# AE302F80C1557LE_CM55_HE_View register map
Vendor: Alif Semiconductor; Series: E3; File version: 1.0
CPU: CM55 r1p0, selectable endian, MPU, FPU, double-precision FPU, DSP, VTOR, 8 interrupt priority bits, 1 SAU regions
Registers are 32-bit, read-write, reset 0x0 unless marked. A register's access mark holds for its fields unless they carry their own. Offsets are from the block's base; [hi:lo] are bit positions; 'fields as' and 'values as' point back to an identical list; <NAME> marks a mode.

## ETH (part 2 of 3)
Base 0x48100000
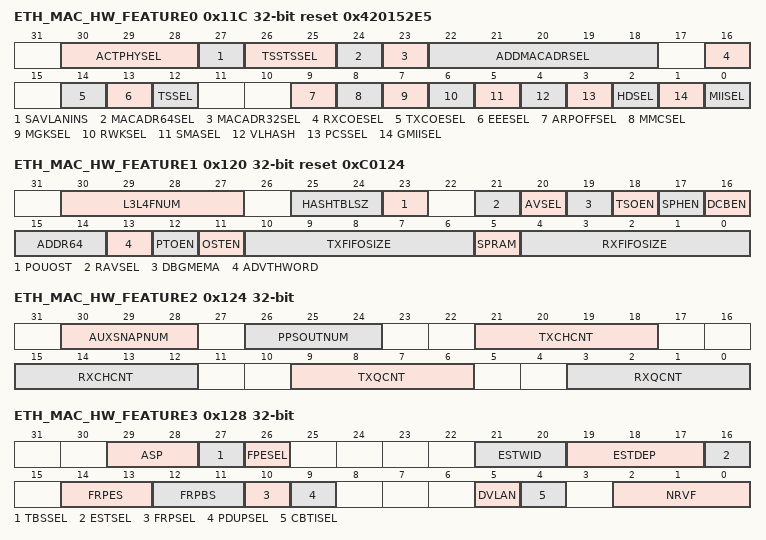
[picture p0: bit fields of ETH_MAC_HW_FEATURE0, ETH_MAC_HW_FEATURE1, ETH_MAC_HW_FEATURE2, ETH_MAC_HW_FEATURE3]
0x11C ETH_MAC_HW_FEATURE0 ro reset 0x420152E5 — ETH Hardware Feature Register 0
  [30:28] ACTPHYSEL — Active PHY Selected
    4=RMII
  [27] SAVLANINS — Source Address or VLAN Insertion Enable
    0=Source address or VLAN insertion disabled
  [26:25] TSSTSSEL — Timestamp System Time Source
    1=External
  [24] MACADR64SEL — MAC Addresses 64-127 Selected
    0=MAC addresses 64-127 disabled
  [23] MACADR32SEL — MAC Addresses 32-63 Selected
    0=MAC addresses 32-63 disabled
  [22:18] ADDMACADRSEL — MAC Addresses 1-31 Selected
    0=MAC addresses 1-31 disabled
  [16] RXCOESEL — Receive Checksum Offload Enabled
    1=Receive checksum offload enabled
  [14] TXCOESEL — Transmit Checksum Offload Enabled
    1=Transmit checksum offload enabled
  [13] EEESEL — Energy Efficient Ethernet Enabled
    0=Energy efficient ethernet disabled
  [12] TSSEL — IEEE 1588-2008 Timestamp Enabled
    1=IEEE 1588-2008 timestamp enabled
  [9] ARPOFFSEL — ARP Offload Enabled
    1=ARP offload disabled
  [8] MMCSEL — RMON Module Enable
    0=RMON module disabled
  [7] MGKSEL — PMT Magic Packet Enable
    1=PMT magic packet enabled
  [6] RWKSEL — PMT Remote Wake-up Packet Enable
    1=PMT remote wake-up packet enabled
  [5] SMASEL — SMA (MDIO) Interface
    1=SMA (MDIO) interface selected
  [4] VLHASH — VLAN Hash Filter Selected
    0=VLAN hash filter not selected
  [3] PCSSEL — PCS Registers (TBI, SGMII, or RTBI PHY interface)
    0=No PCS registers (TBI, SGMII, or RTBI PHY interface)
  [2] HDSEL — Half-duplex Support
    1=Half-duplex supported
  [1] GMIISEL — 1000 Mbps Support
    0=No 1000 Mbps supported
  [0] MIISEL — 10 or 100 Mbps Support
    1=10 or 100 Mbps supported
0x120 ETH_MAC_HW_FEATURE1 ro reset 0xC0124 — ETH Hardware Feature Register 1
  [30:27] L3L4FNUM — Total number of L3 or L4 Filters
    0=No L3 or L4 filter
  [25:24] HASHTBLSZ — Hash Table Size
    0=No hash table
  [23] POUOST — One Step for PTP over UDP/IP Enable
    0=One step for PTP over UDP/IP is disabled
  [21] RAVSEL — Rx Side Only AV Enable
    0=Rx side only AV is disabled
  [20] AVSEL — AV Enable
    0=AV fature is disabled
  [19] DBGMEMA — DMA Debug Registers Enable
    1=DMA debug registers enabled
  [18] TSOEN — TCP Segmentation Offload Enable
    1=TCP segmentation offload is enabled
  [17] SPHEN — Split Header Enable
    0=Split header is disabled
  [16] DCBEN — DCB Enable
    0=DCB is not selected
  [15:14] ADDR64 — Address Width.
    0=32
  [13] ADVTHWORD — IEEE 1588 High Word Register Enable
    0=IEEE 1588 high word register is disabled
  [12] PTOEN — PTP Offload Enable
    0=PTP offload is disabled
  [11] OSTEN — One-Step Timestamping Enable
    0=One-step timestamping is disabled
  [10:6] TXFIFOSIZE — MTL Transmit FIFO Size
    4=2048 bytes
  [5] SPRAM — Single Port RAM Enable
    1=Single port RAM is enabled
  [4:0] RXFIFOSIZE — MTL Receive FIFO Size
    4=2048 bytes
0x124 ETH_MAC_HW_FEATURE2 ro — ETH Hardware Feature Register 2
  [30:28] AUXSNAPNUM — Number of Auxiliary Snapshot Inputs
    0=No auxiliary input
  [26:24] PPSOUTNUM — Number of PPS Outputs
    0=No PPS output
  [21:18] TXCHCNT — Number of DMA Transmit Channels
    0=1 DMA Tx channel
  [15:12] RXCHCNT — Number of DMA Receive Channels
    0=1 DMA Rx channel
  [9:6] TXQCNT — Number of MTL Transmit Queues
    0=1 MTL Tx Queue
  [3:0] RXQCNT — Number of MTL Receive Queues
    0=1 MTL Rx Queue
0x128 ETH_MAC_HW_FEATURE3 ro — ETH Hardware Feature Register 3
  [29:28] ASP — Automotive Safety Package
    0=No safety features selected
  [27] TBSSEL — Time Based Scheduling Enable
    0=Time based scheduling disabled
  [26] FPESEL — Frame Preemption Enable
    0=Frame preemption disabled
  [21:20] ESTWID — Width of the Time Interval field in the Gate Control List
    0=Width not configured
  [19:17] ESTDEP — Depth of the Gate Control List
    0=No depth configured
  [16] ESTSEL — Enhancements to Scheduled Traffic Enable
    0=Enhancements to scheduling traffic disabled
  [14:13] FRPES — Flexible Receive Parser Table Entries size
    0=64 entries
  [12:11] FRPBS — Flexible Receive Parser Buffer size
    0=64 bytes
  [10] FRPSEL — Flexible Receive Parser Select
    0=Flexible receive parser disabled
  [9] PDUPSEL — Broadcast/Multicast Packet Duplication
    0=Broadcast/multicast packet duplication disabled
  [5] DVLAN — Double VLAN Tag Processing Select
    0=Double VLAN tag processing disabled
  [4] CBTISEL — Queue/Channel based VLAN tag insertion on Tx Enable
    0=Queue/Channel based VLAN tag insertion on Tx disabled
  [2:0] NRVF — Number of Extended VLAN Tag Filters Enable
    0=No extended Rx VLAN filters
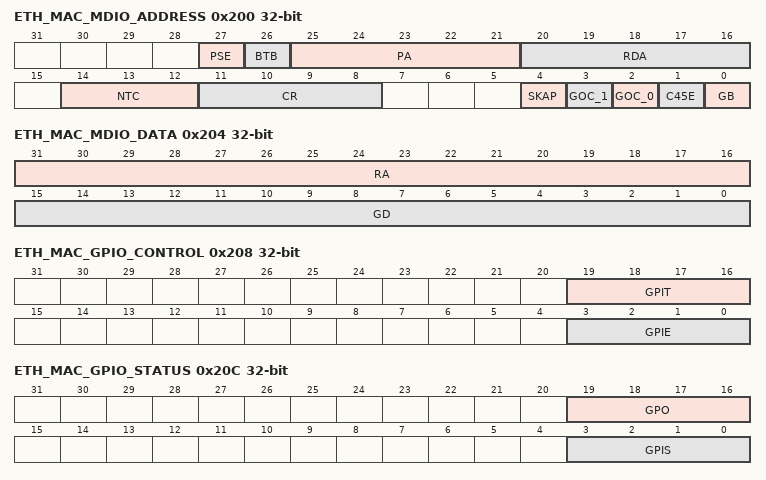
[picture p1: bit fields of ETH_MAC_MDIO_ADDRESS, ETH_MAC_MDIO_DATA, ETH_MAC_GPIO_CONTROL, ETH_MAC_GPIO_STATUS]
0x200 ETH_MAC_MDIO_ADDRESS — MDIO Address Register
  [27] PSE — Preamble Suppression Enable When this bit is set, the MDIO suppresses the 32-bit preamble and transmits MDIO packets with only 1 preamble bit. When this bit is 0, the MDIO packets always has 32 bits of preamble as defined in the IEEE specifications.
    0=Preamble suppression disabled; 1=Preamble suppression enabled
  [26] BTB — Back to Back Transactions When this bit is set and the NTC has value greater than 0, then the MAC informs the completion of a read or write command at the end of frame transfer (before the trailing clocks are transmitted). The software can thus initiate the next command which is executed immediately irrespective of the number trailing clocks generated for the previous frame. When this bit is reset, then the read/write command completion (GB is cleared) only after the trailing clocks are generated. In this mode, it is ensured that the NTC is always generated after each frame. This bit must not be set when NTC = 0.
    0=Back to back transactions disabled; 1=Back to back transactions enabled
  [25:21] PA — Physical Layer Address Specifies the address of the PHY device, out of the 32 possible PHY devices. Note: The value programmed in the C45E field determines if the PHY device is Clause 45 capable or Clause 22 capable.
  [20:16] RDA — Register or Device Address - For Clause 22 PHY: Specifies the PHY register address of the selected PHY device. - For Clause 45 PHY: Specifies the selected MDIO device.
  [14:12] NTC — Number of Trailing Clocks This field controls the number of trailing clock cycles generated on ETH_MDC after the end of MDIO frame transfer. The valid values can be from 0 to 7. When this field is programmed with a value of 0x3, MAC generates three clock cycles on the ETH_MDC line after the end of MDIO frame transfer.
  [11:8] CR — CSR Clock (CLK_CSR) Range The CLK_CSR range selection determines the frequency of the MDC clock (ETH_MDC) according to the CLK_CSR frequency: The suggested range of CLK_CSR frequency applicable for each value (when Bit 11 = 0) ensures that the ETH_MDC is approximately between 1.0 MHz to 2.5 MHz freqency range. When Bit 11 is set, the user can achieve a higher frequency of the ETH_MDC than the frequency limit of 2.5 MHz (specified in the IEEE 802.3 Specification) and program a clock divider of lower value. For example, when CLK_CSR is of 100 MHz frequency and the user programs the CR field to 0xA, the resultant ETH_MDC is of 12.5 MHz which is beyond the range specified in IEEE 802.3 Specification. Program the following values only if the interfacing chips support faster MDC clocks:
    0=CLK_CSR = 60-100 MHz; ETH_MDC = CLK_CSR / 42; 1=CLK_CSR = 100-150 MHz; ETH_MDC = CLK_CSR / 62; 2=CLK_CSR = 20-35 MHz; ETH_MDC = CLK_CSR / 16; 3=CLK_CSR = 35-60 MHz; ETH_MDC = CLK_CSR / 26; 4=CLK_CSR = 150-250 MHz; ETH_MDC = CLK_CSR / 102; 5=CLK_CSR = 250-300 MHz; ETH_MDC = CLK_CSR / 124; 6=CLK_CSR = 300-500 MHz; ETH_MDC = CLK_CSR / 204; 7=CLK_CSR = 500-800 MHz; ETH_MDC = CLK_CSR / 324; 8=CLK_CSR / 4; 9=CLK_CSR / 6; 10=CLK_CSR / 8; 11=CLK_CSR / 10; 12=CLK_CSR / 12; 13=CLK_CSR / 14; 14=CLK_CSR / 16; 15=CLK_CSR / 18
  [4] SKAP — Skip Address Packet When this bit is set, the MDIO does not send the address packets before read, write, or post-read increment address packets. This bit is valid only when the C45E bit is set.
    0=Skip address packet is disabled; 1=Skip address packet is enabled
  [3] GOC_1 — Operation Command 1 This is the higher bit of the operation command to the PHY. GOC_1 and GOC_O are encoded as follows: 0x0: Reserved 0x1: Write 0x2: Post read increment address for Clause 45 PHY 0x3: Read GOC_1 is encoded as follows: 0x0: Operation command 1 is disabled 0x1: Operation command 1 is enabled
  [2] GOC_0 — Operation Command 0 This is the lower bit of the operation command to the PHY. When in MDIO mode (MDIO master) this bit along with GOC_1 determines the operation to be performed to the PHY.
    0=Operation command 0 is disabled; 1=Operation command 0 is enabled
  [1] C45E — Clause 45 PHY Enable When this bit is set, Clause 45 capable PHY is connected to MDIO. When this bit is reset, Clause 22 capable PHY is connected to MDIO.
    0=Clause 45 PHY is disabled; 1=Clause 45 PHY is enabled
  [0] GB — RMII Busy The application sets this bit to instruct the MDIO to initiate a Read or Write access to the MDIO slave. The MAC clears this bit after the MDIO frame transfer is completed. Hence the software must not write or change any of the fields in ETH_MAC_MDIO_ADDRESS and ETH_MAC_MDIO_DATA registers as long as this bit is set. For write transfers, the application must first write 16-bit data in the ETH_MAC_MDIO_DATA[GD] field (and also ETH_MAC_MDIO_DATA[RA] field when the C45E bit is set) before setting this bit. When the C45E bit is set, it should also write into the ETH_MAC_MDIO_DATA[RA] field before initiating a read transfer. When a read transfer is completed (GB=0), the data read from the PHY register is valid in the ETH_MAC_MDIO_DATA[GD] field. Access restriction applies. Setting 1 sets. Self-cleared. Setting 0 has no effect.
    0=RMII busy is disabled; 1=RMII busy is enabled
0x204 ETH_MAC_MDIO_DATA — MDIO Data Register
  [31:16] RA — Register Address This field is valid only when the ETH_MAC_MDIO_ADDRESS[C45E] bit is set. It contains the Register Address in the PHY to which the MDIO frame is intended for.
  [15:0] GD — RMII Data This field contains the 16-bit data value read from the PHY after a Management Read operation or the 16-bit data value to be written to the PHY before a Management Write operation.
0x208 ETH_MAC_GPIO_CONTROL — GPIO Control Register
  [19:16] GPIT — GPI Type When a bit in this field is set, it indicates that the corresponding bit in the ETH_MAC_GPIO_STATUS[GPIS] field is of latched-low (LL) type. When a bit in this field is reset, it indicates that the corresponding bit in the ETH_MAC_GPIO_STATUS[GPIS] field is of latched-high (LH) type.
  [3:0] GPIE — GPI Interrupt Enable When a bit in this field is set and the programmed event (LL or LH) occurs on the corresponding bit in the ETH_MAC_GPIO_STATUS[GPIS] field, the ETH_MAC_INTERRUPT_STATUS[GPIIS] bit is set and an interrupt is generated on the ETH_SBD_IRQ signal. The ETH_MAC_INTERRUPT_STATUS[GPIIS] bit is cleared when the application reads the ETH_MAC_GPIO_STATUS[GPIS] field. When a bit in this field is reset, the ETH_MAC_INTERRUPT_STATUS[GPIIS] bit is not set when any event occurs on the corresponding bit in the ETH_MAC_GPIO_STATUS[GPIS] field.
0x20C ETH_MAC_GPIO_STATUS — GPIO Status Register
  [19:16] GPO — General Purpose Output When a bit in this field is set, it directly drives the corresponding bit of the GPO_O output port. When a bit in this field is reset, it does not directly drive the corresponding bit of the GPO_O output port.
  [3:0] GPIS — General Purpose Input Status This field gives the status of the signals connected to the GPI_I port. Each bit in this field is of the following types based on the setting of the corresponding bit in the ETH_MAC_GPIO_CONTROL[GPIT] field: - Latched-low (LL): This field is cleared when the corresponding GPI_I input becomes low. This field remains low until the application reads it after which this field reflects the current value of GPI_I input. - Latched-high (LH): This field is set when the corresponding GPI_I input becomes high. This field remains high until the application reads it after which this field reflects the current value of GPI_I input.
0x210 ETH_MAC_ARP_ADDRESS — ARP Address Register
  [31:0] ARPPA — ARP Protocol Address This field contains the IPv4 Destination Address of the MAC. This address is used for perfect match with the Protocol Address of Target field in the received ARP packet. This field is available only when the Enable IPv4 ARP Offload option is selected.
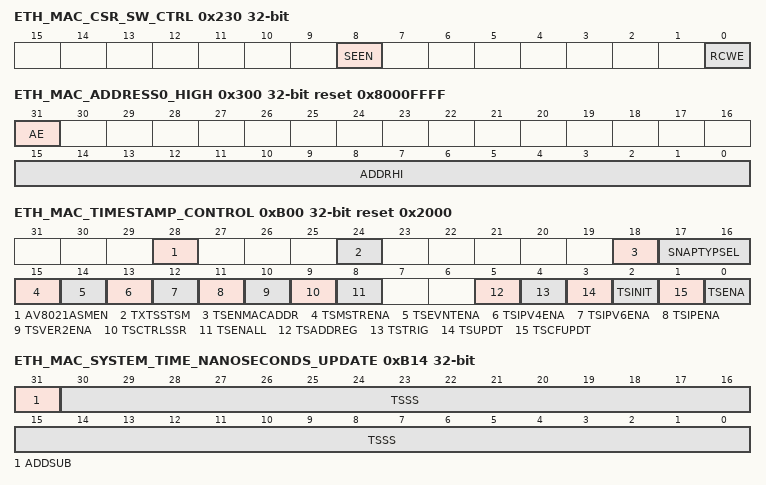
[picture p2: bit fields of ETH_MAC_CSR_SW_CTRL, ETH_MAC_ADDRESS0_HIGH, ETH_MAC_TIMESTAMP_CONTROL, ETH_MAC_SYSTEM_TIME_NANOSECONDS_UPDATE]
0x230 ETH_MAC_CSR_SW_CTRL — CSR Software Control Register
  [8] SEEN — Slave Error Response Enable When this bit is set, the MAC responds with Slave Error for accesses to reserved registers in CSR space. When this bit is reset, the MAC responds with OKAY response to any register accessed from CSR space.
    0=Slave error response is disabled; 1=Slave error response is enabled
  [0] RCWE — Register Clear on Write 1 Enable When this bit is set, the access mode of some register fields changes to Clear on Write 1, the application needs to set that respective bit to 1 to clear it. When this bit is reset, the access mode of these register fields remain as Clear on Read.
    0=Register clear on write 1 is disabled; 1=Register clear on write 1 is enabled
0x300 ETH_MAC_ADDRESS0_HIGH reset 0x8000FFFF — MAC Address 0 High Register
  [31] AE ro — Address Enable This bit is always set to 1.
    0=Ivalid. This bit must be always set to 1; 1=This bit is always set to 1
  [15:0] ADDRHI — MAC Address0[47-32] This field contains the upper 16 bits [47-32] of the first 6-byte MAC address. The MAC uses this field for filtering the received packets and inserting the MAC address in the Transmit Flow Control (Pause) Packets.
0x304 ETH_MAC_ADDRESS0_LOW reset 0xFFFFFFFF — MAC Address 0 Low Register
  [31:0] ADDRLO — MAC Address0[31-0] This field contains the lower 32 bits of the first 6-byte MAC address. The MAC uses this field for filtering the received packets and inserting the MAC address in the Transmit Flow Control (Pause) Packets.
0xB00 ETH_MAC_TIMESTAMP_CONTROL reset 0x2000 — Timestamp Control Register
  [28] AV8021ASMEN — AV 802.1AS Mode Enable When this bit is set, the MAC processes only untagged PTP over Ethernet packets for providing PTP status and capturing timestamp snapshots, that is, IEEE 802.1AS mode of operation.
    0=AV 802.1AS mode is disabled; 1=AV 802.1AS mode is enabled
  [24] TXTSSTSM — Transmit Timestamp Status Mode When this bit is set, the MAC overwrites the earlier transmit timestamp status even if it is not read by the software. The MAC indicates this by setting the ETH_MAC_TX_TIMESTAMP_STATUS_NANOSECONDS[TXTSSMIS] bit. When this bit is reset, the MAC ignores the timestamp status of current packet if the timestamp status of previous packet is not read by the software. The MAC indicates this by setting the ETH_MAC_TX_TIMESTAMP_STATUS_NANOSECONDS[TXTSSMIS] bit.
    0=Transmit timestamp status mode is disabled; 1=Transmit timestamp status mode is enabled
  [18] TSENMACADDR — Enable MAC Address for PTP Packet Filtering When this bit is set, the DA MAC address (that matches ETH_MAC_ADDRESS0_HIGH[ADDRHI] and ETH_MAC_ADDRESS0_LOW[ADDRLO]) is used to filter the PTP packets when PTP is directly sent over Ethernet. When this bit is set, received PTP packets with DA containing a special multicast or unicast address that matches the one programmed in the ETH_MAC_ADDRESS0_HIGH and ETH_MAC_ADDRESS0_LOW registers are considered for processing, when PTP is directly sent over Ethernet.
    0=MAC address for PTP packet filtering is disabled; 1=MAC address for PTP packet filtering is enabled
  [17:16] SNAPTYPSEL — Select PTP packets for Taking Snapshots This field, along with the TSMSTRENA and TSEVNTENA bits, decide the set of PTP packet types for which snapshot needs to be taken. The encoding is as follows: - SNAPTYPSEL = 0x0; TSMSTRENA = X; TSEVNTENA = 0x0: SYNC, Follow_Up, Delay_Req, Delay_Resp - SNAPTYPSEL = 0x0; TSMSTRENA = 0x0; TSEVNTENA = 0x1: SYNC - SNAPTYPSEL = 0x0; TSMSTRENA = 0x1; TSEVNTENA = 0x1: Delay_Req - SNAPTYPSEL = 0x1; TSMSTRENA = X; TSEVNTENA = 0x0: SYNC, Follow_Up, Delay_Req, Delay_Resp, Pdelay_Req, Pdelay_Resp, Pdelay_Resp_Follow_Up - SNAPTYPSEL = 0x1; TSMSTRENA = 0x0; TSEVNTENA = 0x1: SYNC, Pdelay_Req, Pdelay_Resp - SNAPTYPSEL = 0x1; TSMSTRENA = 0x1; TSEVNTENA = 0x1: Delay_Req, Pdelay_Req, Pdelay_Resp - SNAPTYPSEL = 0x2; TSMSTRENA = X; TSEVNTENA = X: SYNC, Delay_Req - SNAPTYPSEL = 0x3; TSMSTRENA = X; TSEVNTENA = X: Pdelay_Req, Pdelay_Resp Note: X means 'don't care'.
  [15] TSMSTRENA — Enable Snapshot for Messages Relevant to Master When this bit is set, the snapshot is taken only for the messages that are relevant to the master node. Otherwise, the snapshot is taken for the messages relevant to the slave node.
    0=Snapshot for messages relevant to master is disabled; 1=Snapshot for messages relevant to master is enabled
  [14] TSEVNTENA — Enable Timestamp Snapshot for Event Messages When this bit is set, the timestamp snapshot is taken only for event messages (SYNC, Delay_Req, Pdelay_Req, or Pdelay_Resp). When this bit is reset, the snapshot is taken for all messages except Announce, Management, and Signaling.
    0=Timestamp snapshot for event messages is disabled; 1=Timestamp snapshot for event messages is enabled
  [13] TSIPV4ENA — Enable Processing of PTP Packets Sent over IPv4-UDP When this bit is set, the MAC receiver processes the PTP packets encapsulated in IPv4-UDP packets. When this bit is reset, the MAC ignores the PTP transported over IPv4-UDP packets. This bit is set by default.
    0=Processing of PTP packets sent over IPv4-UDP is disabled; 1=Processing of PTP packets sent over IPv4-UDP is enabled
  [12] TSIPV6ENA — Enable Processing of PTP Packets Sent over IPv6-UDP When this bit is set, the MAC receiver processes the PTP packets encapsulated in IPv6-UDP packets. When this bit is clear, the MAC ignores the PTP transported over IPv6-UDP packets.
    0=Processing of PTP packets sent over IPv6-UDP is disabled; 1=Processing of PTP packets sent over IPv6-UDP is enabled
  [11] TSIPENA — Enable Processing of PTP over Ethernet Packets When this bit is set, the MAC receiver processes the PTP packets encapsulated directly in the Ethernet packets. When this bit is reset, the MAC ignores the PTP over Ethernet packets.
    0=Processing of PTP over Ethernet packets is disabled; 1=Processing of PTP over Ethernet packets is enabled
  [10] TSVER2ENA — Enable PTP Packet Processing for Version 2 Format When this bit is set, the IEEE 1588 version 2 format is used to process the PTP packets. When this bit is reset, the IEEE 1588 version 1 format is used to process the PTP packets.
    0=PTP packet processing for version 2 format is disabled; 1=PTP packet processing for version 2 format is enabled
  [9] TSCTRLSSR — Timestamp Digital or Binary Rollover Control When this bit is set, the ETH_MAC_SYSTEM_TIME_NANOSECONDS register rolls over after 0x3B9A_C9FF value (that is, 1 nanosecond accuracy) and increments the ETH_MAC_SYSTEM_TIME_SECONDS register. When this bit is reset, the rollover value of the ETH_MAC_SYSTEM_TIME_NANOSECONDS register is 0x7FFF_FFFF. The sub-second increment must be programmed correctly depending on the CLK_PTP frequency and the value of this bit.
    0=Timestamp digital or binary rollover control is disabled; 1=Timestamp digital or binary rollover control is enabled
  [8] TSENALL — Enable Timestamp for All Packets When this bit is set, the timestamp snapshot is enabled for all packets received by the MAC.
    0=Timestamp for all packets disabled; 1=Timestamp for all packets enabled
  [5] TSADDREG — Update the ETH_MAC_TIMESTAMP_ADDEND register When this bit is set, the content of the ETH_MAC_TIMESTAMP_ADDEND register is updated in the PTP block for fine correction. This bit is cleared when the update is complete. This bit must be zero before it is set. Access restriction applies. Setting 1 sets. Self-cleared. Setting 0 has no effect.
    0=Addend register is not updated; 1=Addend register is updated
  [4] TSTRIG — Enable Timestamp Interrupt Trigger When this bit is set, the timestamp interrupt is generated when the System Time becomes greater than the value written in the Target Time register. This bit is reset after the Timestamp Trigger Interrupt is generated. Access restriction applies. Setting 1 sets. Self-cleared. Setting 0 has no effect.
    0=Timestamp interrupt trigger is not enabled; 1=Timestamp interrupt trigger is enabled
  [3] TSUPDT — Update Timestamp When this bit is set, the system time is updated (added or subtracted) with the value specified in ETH_MAC_SYSTEM_TIME_SECONDS_UPDATE and ETH_MAC_SYSTEM_TIME_NANOSECONDS_UPDATE registers. This bit must be zero before updating it. This bit is reset when the update is complete in hardware. Access restriction applies. Setting 1 sets. Self-cleared. Setting 0 has no effect.
    0=Timestamp is not updated; 1=Timestamp is updated
  [2] TSINIT — Initialize Timestamp When this bit is set, the system time is initialized (overwritten) with the value specified in the ETH_MAC_SYSTEM_TIME_SECONDS_UPDATE and ETH_MAC_SYSTEM_TIME_NANOSECONDS_UPDATE registers. This bit must be zero before it is updated. This bit is reset when the initialization is complete. Only the ETH_MAC_SYSTEM_TIME_SECONDS register can be initialized. Access restriction applies. Setting 1 sets. Self-cleared. Setting 0 has no effect.
    0=Timestamp is not initialized; 1=Timestamp is initialized
  [1] TSCFUPDT — Fine or Coarse Timestamp Update When this bit is set, the Fine method is used to update system timestamp. When this bit is reset, Coarse method is used to update the system timestamp.
    0=Coarse method is used to update system timestamp; 1=Fine method is used to update system timestamp
  [0] TSENA — Enable Timestamp When this bit is set, the timestamp is added for Transmit and Receive packets. When disabled, timestamp is not added for transmit and receive packets and the Timestamp Generator is also suspended. The user needs to initialize the Timestamp (system time) after enabling this mode. On the Receive side, the MAC processes the 1588 packets only if this bit is set.
    0=Timestamp is disabled; 1=Timestamp is enabled
0xB04 ETH_MAC_SUB_SECOND_INCREMENT — Sub-second Increment Register
  [23:16] SSINC — Sub-second Increment Value The value programmed in this field is accumulated every clock cycle (of CLK_PTP) with the contents of the ETH_MAC_SYSTEM_TIME_NANOSECONDS register. For example, when the PTP clock is 50 MHz (period is 20 ns), the user must program 20 (0x14) when the ETH_MAC_SYSTEM_TIME_NANOSECONDS register has an accuracy of 1 ns (the ETH_MAC_TIMESTAMP_CONTROL[TSCTRLSSR] bit is set). When TSCTRLSSR is cleard, the ETH_MAC_SYSTEM_TIME_NANOSECONDS register has a resolution of ~0.465 ns. In this case, the user must program a value of 43 (0x2B) which is derived by 20 ns/0.465.
0xB08 ETH_MAC_SYSTEM_TIME_SECONDS ro — System Time Seconds Register
  [31:0] TSS — Timestamp Second The value in this field indicates the current value in seconds of the System Time maintained by the MAC.
0xB0C ETH_MAC_SYSTEM_TIME_NANOSECONDS ro — System Time Nanoseconds Register
  [30:0] TSSS — Timestamp Sub Seconds The value in this field has the sub-second representation of time, with an accuracy of 0.46 ns. When the ETH_MAC_TIMESTAMP_CONTROL[TSCTRLSSR] bit is set, each bit represents 1 ns. The maximum value is 0x3B9A_C9FF after which it rolls-over to zero.
0xB10 ETH_MAC_SYSTEM_TIME_SECONDS_UPDATE — System Time Seconds Update Register
  [31:0] TSS — Timestamp Seconds The value in this field is the seconds part of the update. When ETH_MAC_SYSTEM_TIME_NANOSECONDS_UPDATE[ADDSUB] is reset, this field must be programmed with the seconds part of the update value. When ETH_MAC_SYSTEM_TIME_NANOSECONDS_UPDATE[ADDSUB] is set, this field must be programmed with the complement of the seconds part of the update value. For example, to subtract 2.000000001 seconds from the system time, the TSS field must be 0xFFFF_FFFE (that is, 2^32 - 2).
0xB14 ETH_MAC_SYSTEM_TIME_NANOSECONDS_UPDATE — System Time Nanoseconds Update Register
  [31] ADDSUB — Add or Subtract Time When this bit is set, the time value is subtracted with the contents of the update register. When this bit is reset, the time value is added with the contents of the update register.
    0=Add time; 1=Subtract time
  [30:0] TSSS — Timestamp Sub Seconds The value in this field is the sub-seconds part of the update. When ETH_MAC_SYSTEM_TIME_NANOSECONDS_UPDATE[ADDSUB] is reset, this field must be programmed with the sub-seconds part of the update value, with an accuracy based on the ETH_MAC_TIMESTAMP_CONTROL[TSCTRLSSR] bit. When ETH_MAC_SYSTEM_TIME_NANOSECONDS_UPDATE[ADDSUB] is set, this field must be programmed with the complement of the sub-seconds part of the update value as described below. When the ETH_MAC_TIMESTAMP_CONTROL[TSCTRLSSR] bit set, the programmed value must be 10^9 - <sub-second value>. When the ETH_MAC_TIMESTAMP_CONTROL[TSCTRLSSR] bit reset, the programmed value must be 2^31 - <sub-second_value>. When the TSCTRLSSR bit is reset in the ETH_MAC_TIMESTAMP_CONTROL register, each bit represents an accuracy of 0.46 ns. When the TSCTRLSSR bit is set in the ETH_MAC_TIMESTAMP_CONTROL register, each bit represents 1 ns and the programmed value should not exceed 0x3B9A_C9FF. For example, to subtract 2.000000001 seconds from the system time, then the TSSS field must be 0x7FFF_FFFF (that is, 2^31 - 1), when the ETH_MAC_TIMESTAMP_CONTROL[TSCTRLSSR] bit reset and 0x3B9A_C9FF (that is, 10^9 - 1), when the ETH_MAC_TIMESTAMP_CONTROL[TSCTRLSSR] bit set.
0xB18 ETH_MAC_TIMESTAMP_ADDEND — Timestamp Addend Register
  [31:0] TSAR — Timestamp Addend Register This field indicates the 32-bit time value to be added to the Accumulator register to achieve time synchronization.
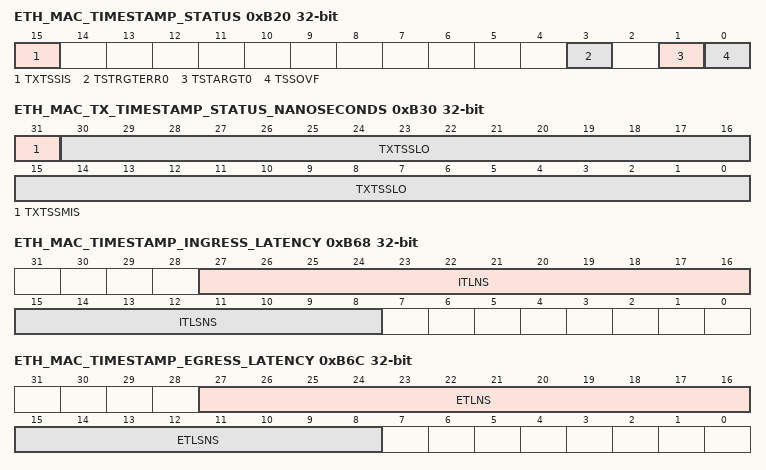
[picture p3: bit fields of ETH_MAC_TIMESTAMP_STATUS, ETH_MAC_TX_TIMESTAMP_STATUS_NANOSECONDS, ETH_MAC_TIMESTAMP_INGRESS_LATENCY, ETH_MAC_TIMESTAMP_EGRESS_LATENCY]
0xB20 ETH_MAC_TIMESTAMP_STATUS ro — Timestamp Status Register
  [15] TXTSSIS — Tx Timestamp Status Interrupt Status When drop transmit status is enabled in MTL, this bit is set when the captured transmit timestamp is updated in the ETH_MAC_TX_TIMESTAMP_STATUS_NANOSECONDS and ETH_MAC_TX_TIMESTAMP_STATUS_SECONDS registers. This bit is cleared when the ETH_MAC_TX_TIMESTAMP_STATUS_SECONDS register is read (or write to ETH_MAC_TX_TIMESTAMP_STATUS_SECONDS register when the ETH_MAC_CSR_SW_CTRL[RCWE] bit is set).
    0=Tx timestamp status interrupt status not detected; 1=Tx timestamp status interrupt status detected
  [3] TSTRGTERR0 — Timestamp Target Time Error This bit is set when the latest target time programmed in the ETH_MAC_PPS0_TARGET_TIME_SECONDS and ETH_MAC_PPS0_TARGET_TIME_NANOSECONDS registers elapses. Access restriction applies. Clears on read (or this bit is written to 1 when the ETH_MAC_CSR_SW_CTRL[RCWE] bit is set). Self-set to 1 on internal event.
    0=Timestamp target time error status not detected; 1=Timestamp target time error status detected
  [1] TSTARGT0 — Timestamp Target Time Reached When this bit is set, it indicates that the value of system time is greater than or equal to the value specified in the ETH_MAC_PPS0_TARGET_TIME_SECONDS and ETH_MAC_PPS0_TARGET_TIME_NANOSECONDS registers. Access restriction applies. Clears on read (or this bit is written to 1 when the ETH_MAC_CSR_SW_CTRL[RCWE] bit is set). Self-set to 1 on internal event.
    0=Timestamp target time reached status not detected; 1=Timestamp target time reached status detected
  [0] TSSOVF — Timestamp Seconds Overflow When this bit is set, it indicates that the ETH_MAC_SYSTEM_TIME_SECONDS[TSS] value has overflowed beyond 0xFFFF_FFFF. Access restriction applies. Clears on read (or this bit is written to 1 when the ETH_MAC_CSR_SW_CTRL[RCWE] bit is set). Self-set to 1 on internal event.
    0=Timestamp seconds overflow status not detected; 1=Timestamp seconds overflow status detected
0xB30 ETH_MAC_TX_TIMESTAMP_STATUS_NANOSECONDS ro — Transmit Timestamp Status Nanoseconds Register
  [31] TXTSSMIS — Transmit Timestamp Status Missed When this bit is set, it indicates one of the following: The timestamp of the current packet is ignored if the ETH_MAC_TIMESTAMP_CONTROL[TXTSSTSM] bit is reset The timestamp of the previous packet is overwritten with timestamp of the current packet if the ETH_MAC_TIMESTAMP_CONTROL[TXTSSTSM] bit is set. Access restriction applies. Clears on read. Self-set to 1 on internal event.
    0=Transmit timestamp status missed status not detected; 1=Transmit timestamp status missed status detected
  [30:0] TXTSSLO — Transmit Timestamp Status Low This field contains the 31 bits of the Nanoseconds field of the Transmit packet's captured timestamp.
0xB34 ETH_MAC_TX_TIMESTAMP_STATUS_SECONDS ro — Transmit Timestamp Status Seconds Register
  [31:0] TXTSSHI — Transmit Timestamp Status High This field contains the lower 32 bits of the Seconds field of Transmit packet's captured timestamp.
0xB58 ETH_MAC_TIMESTAMP_INGRESS_CORR_NANOSECOND — Timestamp Ingress Correction Nanoseconds Register
  [31:0] TSIC — Timestamp Ingress Correction This field contains the ingress path correction value as defined by the Ingress Correction expression.
0xB5C ETH_MAC_TIMESTAMP_EGRESS_CORR_NANOSECOND — Timestamp Egress Correction Nanoseconds Register
  [31:0] TSEC — Timestamp Egress Correction This field contains the nanoseconds part of the egress path correction value as defined by the Egress Correction expression.
0xB68 ETH_MAC_TIMESTAMP_INGRESS_LATENCY ro — Ingress MAC latency Register
  [27:16] ITLNS — Ingress Timestamp Latency, in nanoseconds This register holds the average latency in nanoseconds between the input ports (ETH_RXD[1-0]) of MAC and the actual point (RMII) where the ingress timestamp is taken.
  [15:8] ITLSNS — Ingress Timestamp Latency, in sub-nanoseconds This register holds the average latency in sub-nanoseconds between the input ports (ETH_RXD[1-0]) of MAC and the actual point (RMII) where the ingress timestamp is taken.
0xB6C ETH_MAC_TIMESTAMP_EGRESS_LATENCY ro — Egress MAC latency Register
  [27:16] ETLNS — Egress Timestamp Latency, in nanoseconds This register holds the average latency in nanoseconds between the actual point (RMII) where the egress timestamp is taken and the output ports (ETH_TXD[1-0]) of the MAC.
  [15:8] ETLSNS — Egress Timestamp Latency, in sub-nanoseconds This register holds the average latency in sub-nanoseconds between the actual point (RMII) where the egress timestamp is taken and the output ports (ETH_TXD[1-0]) of the MAC.
0xB70 ETH_MAC_PPS_CONTROL — PPS Control Register
  [3:0] PPSCTRL — Pulse Per Second (PPS) Frequency Control This field controls the PPS frequency. The default value of PPSCTRL is 0x0, and the PPS frequency is 1 pulse every second. For other values of PPSCTRL, the PPS becomes a generated clock of the following frequencies: Note: In the binary rollover mode, the PPS frequency has a duty cycle of 50 percent with these frequencies. In the digital rollover mode, the PPS frequency is an average number. The actual clock is of different frequency that gets synchronized every second. For example: When PPSCTRL = 0x1, the PPS (1 Hz) has a low period of 537 ms and a high period of 463 ms When PPSCTRL = 0x2, the PPS (2 Hz) is a sequence of: - One clock of 50 percent duty cycle and 537 ms period - Second clock of 463 ms period (268 ms low and 195 ms high) When PPSCTRL = 0x3, the PPS (4 Hz) is a sequence of: - Fourth clock of 195 ms period (134 ms low and 61 ms high) This behavior is because of the non-linear toggling of bits in the digital rollover mode in the ETH_MAC_SYSTEM_TIME_NANOSECONDS register.
    1=The binary rollover is 2 Hz, and the digital rollover is 1 Hz; 2=The binary rollover is 4 Hz, and the digital rollover is 2 Hz; 3=The binary rollover is 8 Hz, and the digital rollover is 4 Hz; 4=The binary rollover is 16 Hz, and the digital rollover is 8 Hz; 15=The binary rollover is 32.768 kHz and the digital rollover is 16.384 kHz
0xB80 ETH_MAC_PPS0_TARGET_TIME_SECONDS — PPS0 Target Time Seconds Register
  [31:0] TSTRH0 — PPS Target Time Seconds This field stores the time in seconds. When the timestamp value matches or exceeds both ETH_MAC_PPS0_TARGET_TIME_SECONDS and ETH_MAC_PPS0_TARGET_TIME_NANOSECONDS registers, the MAC generates an interrupt (if enabled).
0xB84 ETH_MAC_PPS0_TARGET_TIME_NANOSECONDS — PPS0 Target Time Nanoseconds Register
  [30:0] TTSL0 — Target Time Low for PPS Register This register stores the time in (signed) nanoseconds. When the value of the timestamp matches the value in both ETH_MAC_PPS0_TARGET_TIME_SECONDS and ETH_MAC_PPS0_TARGET_TIME_NANOSECONDS registers, the MAC generates an interrupt (if enabled). When the ETH_MAC_TIMESTAMP_CONTROL[TSCTRLSSR] bit is reset, this value must be (time in ns / 0.465). When the ETH_MAC_TIMESTAMP_CONTROL[TSCTRLSSR] bit is set, this value must not exceed 0x3B9A_C9FF. Access restriction applies. Setting 1 sets. Self-cleared. Setting 0 has no effect.
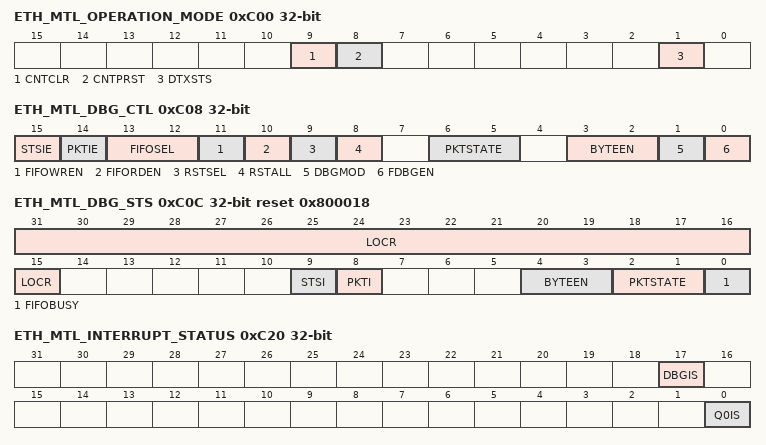
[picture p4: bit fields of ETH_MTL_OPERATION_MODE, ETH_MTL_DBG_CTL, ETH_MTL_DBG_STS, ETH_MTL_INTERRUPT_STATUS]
0xC00 ETH_MTL_OPERATION_MODE — Operation Mode Register
  [9] CNTCLR — Counters Reset When this bit is set, all counters are reset. This bit is cleared automatically after 1 clock cycle. If this bit is set along with the CNTPRST bit, CNTPRST has precedence. Access restrictions apply. MAC initiates the counters reset when application writes 1. MAC writes 0 after the counters reset is complete. MAC ignores when application writes 0.
    0=Counters are not reset; 1=All counters are reset
  [8] CNTPRST — Counters Preset When this bit is set, The ETH_MTL_TXQ0_UNDERFLOW register is initialized/preset to 0x7F0. The ETH_MTL_RXQ0_MISSED_PACKET_OVERFLOW_CNT[MISPKTCNT] and ETH_MTL_RXQ0_MISSED_PACKET_OVERFLOW_CNT[OVFPKTCNT] fields are initialized/preset to 0x7F0. MAC initiates the counters reset when application writes 1. MAC writes 0 after the counters reset is complete. MAC ignores when application writes 0.
    0=Counters preset is disabled; 1=Counters preset is enabled
  [1] DTXSTS — Drop Transmit Status When this bit is set, the Tx packet status received from the MAC is dropped in the MTL. When this bit is reset, the Tx packet status received from the MAC is forwarded to the application.
    0=Drop transmit status is disabled; 1=Drop transmit status is enabled
0xC08 ETH_MTL_DBG_CTL — FIFO Debug Access Control and Status Register
  [15] STSIE — Transmit Status Available Interrupt Status Enable When this bit is set, an interrupt is generated when Transmit status is available in slave mode.
    0=Transmit packet available interrupt status is disabled; 1=Transmit packet available interrupt status is enabled
  [14] PKTIE — Receive Packet Available Interrupt Status Enable When this bit is set, an interrupt is generated when EOP of received packet is written to the Rx FIFO.
    0=Receive packet available interrupt status is disabled; 1=Receive packet available interrupt status is enabled
  [13:12] FIFOSEL — FIFO Selected for Access This field indicates the FIFO selected for debug access:
    0=Tx FIFO; 1=Tx Status FIFO (only read access when SLVMOD is set); 2=TSO FIFO (cannot be accessed when SLVMOD is set); 3=Rx FIFO
  [11] FIFOWREN — FIFO Write Enable When this bit is set, it enables the Write operation on selected FIFO when FIFO Debug Access is enabled. This bit must not be written to 1 when FIFO Debug Access is not enabled, that is FDBGEN bit is 0. Access restriction applies. Self-cleared. Setting 0 clears. Setting 1 sets.
    0=FIFO write is disabled; 1=FIFO write is enabled
  [10] FIFORDEN — FIFO Read Enable When this bit is set, it enables the Read operation on selected FIFO when FIFO Debug Access is enabled. This bit must not be written to 1 when FIFO Debug Access is not enabled, that is FDBGEN bit is 0. Access restriction applies. Self-cleared. Setting 0 clears. Setting 1 sets.
    0=FIFO read is disabled; 1=FIFO read is enabled
  [9] RSTSEL — Reset Pointers of Selected FIFO When this bit is set, the pointers of the currently-selected FIFO are reset when FIFO Debug Access is enabled. This bit must not be written to 1 when FIFO Debug Access is not enabled, that is FDBGEN bit is 0. Access restriction applies. Self-cleared. Setting 0 clears. Setting 1 sets.
    0=Reset pointers of selected FIFO is disabled; 1=Reset pointers of selected FIFO is enabled
  [8] RSTALL — Reset All Pointers When this bit is set, the pointers of all FIFOs are reset when FIFO Debug Access is enabled. This bit must not be written to 1 when FIFO Debug Access is not enabled, that is FDBGEN bit is 0. Access restriction applies. Self-cleared. Setting 0 clears. Setting 1 sets.
    0=Reset all pointers is disabled; 1=Reset all pointers is enabled
  [6:5] PKTSTATE — Encoded Packet State This field is used to write the control information to the Tx FIFO or Rx FIFO. Tx FIFO: 0x0: Packet data 0x1: Control word 0x2: SOP data 0x3: EOP data Rx FIFO: 0x0: Packet data 0x1: Normal status 0x2: Last status 0x3: EOP
  [3:2] BYTEEN — Byte Enables This field indicates the number of data bytes valid in the data register during Write operation. This is valid only when PKTSTATE is 0x2 (EOP) and Tx FIFO or Rx FIFO is selected.
    0=Byte 0 valid; 1=Byte 0 and Byte 1 are valid; 2=Byte 0, Byte 1, and Byte 2 are valid; 3=All four bytes are valid
  [1] DBGMOD — Debug Mode Access to FIFO When this bit is set, it indicates that the current access to the FIFO is read, write, and debug access (that is, data can be written and read to specified or all locations through FIFO Debug Interface). In this mode, the following access types are allowed: - Read and Write access to Tx FIFO, TSO FIFO, and Rx FIFO - Read access is allowed to Tx Status FIFO. When this bit is reset, it indicates that the current access to the FIFO is slave access bypassing the DMA (that is, packets can be transmitted or received through FIFO Debug Interface). In this mode, the following access are allowed: - Write access to the Tx FIFO - Read access to the Rx FIFO and Tx Status FIFO
    0=Debug mode access to FIFO is disabled; 1=Debug mode access to FIFO is enabled
  [0] FDBGEN — FIFO Debug Access Enable When this bit is set, it indicates that the debug mode access to the FIFO through CSR Slave Interface is enabled. When this bit is reset, it indicates that the FIFO can be accessed only through a master interface.
    0=FIFO debug access through CSR Slave Interface is disabled; 1=FIFO debug access through CSR Slave Interface is enabled
0xC0C ETH_MTL_DBG_STS reset 0x800018 — FIFO Debug Status Register
  [31:15] LOCR ro — Remaining Locations in the FIFO Slave Access Mode: This field indicates the space available in the selected FIFO. Debug Access Mode: This field contains the Write or Read pointer value of the selected FIFO during Write or Read operation, respectively.
  [9] STSI — Transmit Status Available Interrupt Status When set, this bit indicates that the Slave mode Tx packet is transmitted, and the status is available in Tx Status FIFO. This bit is reset when 1 is written to this bit.
    0=Transmit status available interrupt status not detected; 1=Transmit status available interrupt status detected
  [8] PKTI — Receive Packet Available Interrupt Status When set, this bit indicates that MAC layer has written the EOP of received packet to the Rx FIFO. This bit is reset when 1 is written to this bit.
    0=Receive packet available interrupt status not detected; 1=Receive packet available interrupt status detected
  [4:3] BYTEEN ro — Byte Enables This field indicates the number of data bytes valid in the data register during Read operation. This is valid only when PKTSTATE is 0x2 (EOP) and Tx FIFO or Rx FIFO is selected.
    values as ETH_MTL_DBG_CTL.BYTEEN
  [2:1] PKTSTATE ro — Encoded Packet State This field is used to get the control or status information of the selected FIFO. Tx FIFO: 0x0: Packet data 0x1: Control word 0x2: SOP data 0x3: EOP data Rx FIFO: 0x0: Packet data 0x1: Normal status 0x2: Last status 0x3: EOP
  [0] FIFOBUSY ro — FIFO Busy When set, this bit indicates that a FIFO operation is in progress in the MAC and content of the following fields is not valid: All other fields of this register All fields of the ETH_MTL_FIFO_DEBUG_DATA register
    0=FIFO busy not detected; 1=FIFO busy detected
0xC10 ETH_MTL_FIFO_DEBUG_DATA — FIFO Debug Data Register
  [31:0] FDBGDATA — FIFO Debug Data During debug or slave access write operation, this field contains the data to be written to the Tx FIFO, Rx FIFO, or TSO FIFO. During debug or slave access read operation, this field contains the data read from the Tx FIFO, Rx FIFO, TSO FIFO, or Tx Status FIFO.
0xC20 ETH_MTL_INTERRUPT_STATUS ro — MTL Interrupt Status Register
  [17] DBGIS — Debug Interrupt status This bit indicates an interrupt event during the slave access. To reset this bit, the application must read the ETH_MTL_DBG_STS register to get the exact cause of the interrupt and clear its source.
    0=Debug interrupt status not detected; 1=Debug interrupt status detected
  [0] Q0IS — Queue 0 Interrupt status This bit indicates that there is an interrupt from Queue 0. To reset this bit, the application must read Queue 0 Interrupt Control and Status register to get the exact cause of the interrupt and clear its source.
    0=Queue 0 interrupt status not detected; 1=Queue 0 interrupt status detected
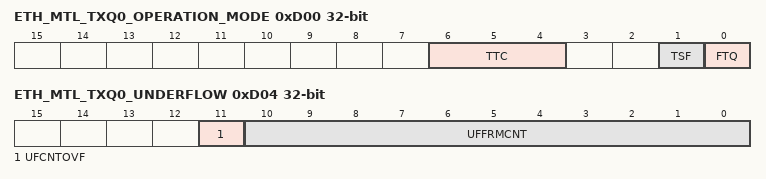
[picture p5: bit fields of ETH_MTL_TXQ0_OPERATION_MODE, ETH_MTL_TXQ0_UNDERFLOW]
0xD00 ETH_MTL_TXQ0_OPERATION_MODE — Queue 0 Transmit Operation Mode Register
  [6:4] TTC — Transmit Threshold Control These bits control the threshold level of the MTL Tx Queue. The transmission starts when the packet size within the MTL Tx Queue is larger than the threshold. In addition, full packets with length less than the threshold are also transmitted. These bits are used only when the TSF bit is reset.
    0=32; 1=64; 2=96; 3=128; 4=192; 5=256; 6=384; 7=512
  [1] TSF — Transmit Store and Forward When this bit is set, the transmission starts when a full packet resides in the MTL Tx Queue. When this bit is set, the TTC value is ignored. This bit should be changed only when the transmission is stopped.
    0=Transmit store and forward is disabled; 1=Transmit store and forward is enabled
  [0] FTQ — Flush Transmit Queue When this bit is set, the Tx Queue controller logic is reset to its default values. Therefore, all the data in the Tx Queue is lost or flushed. This bit is internally reset when the flushing operation is complete. Until this bit is reset, the user must not write to the ETH_MTL_TXQ0_OPERATION_MODE register. The data which is already accepted by the MAC transmitter is not flushed. It is scheduled for transmission and results in underflow and runt packet transmission. Note: The flush operation is complete only when the Tx Queue is empty and the application has accepted the pending Tx Status of all transmitted packets. Access restrictions apply. MAC initiates the Tx queue flush when application writes 1. MAC writes 0 after the Tx queue flush is complete. MAC ignores when application writes 0.
    0=Flush transmit queue is disabled; 1=Flush transmit queue is enabled
0xD04 ETH_MTL_TXQ0_UNDERFLOW ro — Queue 0 Underflow Counter Register
  [11] UFCNTOVF — Overflow Bit for Underflow Packet Counter This bit is set every time the Tx Queue Underflow Packet Counter field overflows, that is, it has crossed the maximum count. In such a scenario, the overflow packet counter is reset to all-zeros and this bit indicates that the rollover happened. Access restriction applies. Clears on read. Self-set to 1 on internal event.
    0=Overflow not detected for underflow packet counter; 1=Overflow detected for underflow packet counter
  [10:0] UFFRMCNT — Underflow Packet Counter This field indicates the number of packets aborted by the controller because of Tx Queue Underflow. This counter is incremented each time the MAC aborts outgoing packet because of underflow. Access restriction applies. Clears on read. Self-set to 1 on internal event.
